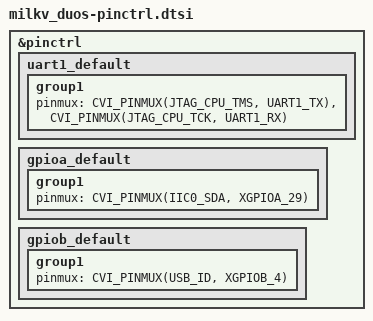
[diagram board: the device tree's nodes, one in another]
/*
 * Copyright (c) 2024 Chen Xingyu <hi@xingrz.me>
 * SPDX-License-Identifier: Apache-2.0
 */

&pinctrl {
	uart1_default: uart1_default {
		group1 {
			pinmux = <CVI_PINMUX(JTAG_CPU_TMS, UART1_TX)>,  /* A19 */
				 <CVI_PINMUX(JTAG_CPU_TCK, UART1_RX)>;  /* A18 */
		};
	};

	gpioa_default: gpioa_default {
		group1 {
			pinmux = <CVI_PINMUX(IIC0_SDA, XGPIOA_29)>;     /* A29, LED */
		};
	};

	gpiob_default: gpiob_default {
		group1 {
			pinmux = <CVI_PINMUX(USB_ID, XGPIOB_4)>;        /* B4, RECOVERY key */
		};
	};
};
